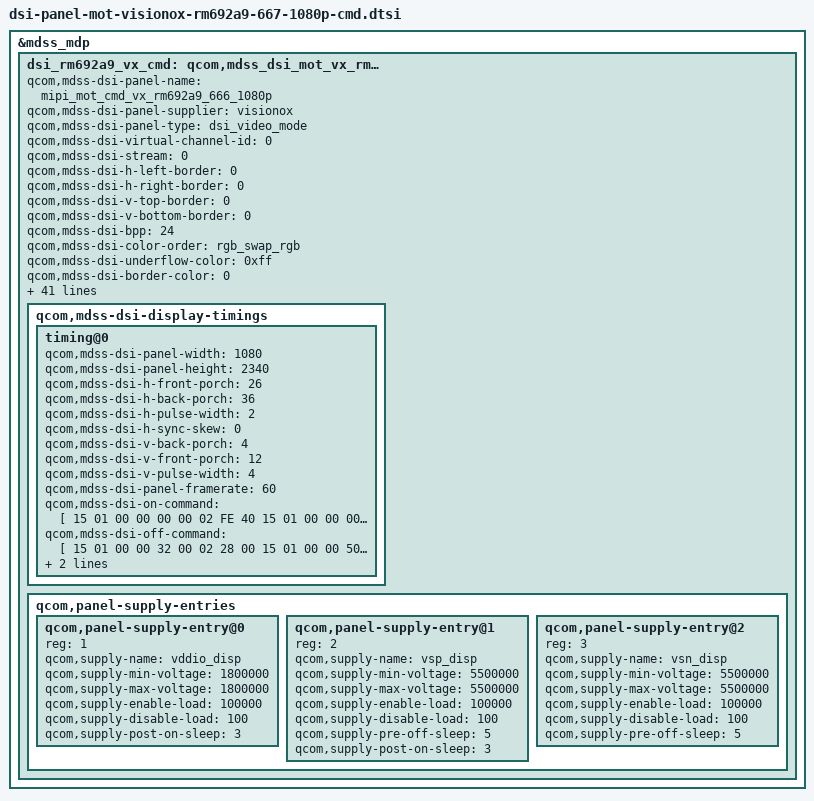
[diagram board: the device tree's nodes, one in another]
/* Copyright (c) 2016-2019, The Linux Foundation. All rights reserved.
 *
 * This program is free software; you can redistribute it and/or modify
 * it under the terms of the GNU General Public License version 2 and
 * only version 2 as published by the Free Software Foundation.
 *
 * This program is distributed in the hope that it will be useful,
 * but WITHOUT ANY WARRANTY; without even the implied warranty of
 * MERCHANTABILITY or FITNESS FOR A PARTICULAR PURPOSE.  See the
 * GNU General Public License for more details.
 */

&mdss_mdp {
	dsi_rm692a9_vx_cmd: qcom,mdss_dsi_mot_vx_rm692a9_667_1080x2340_cmd {
		qcom,mdss-dsi-panel-name = "mipi_mot_cmd_vx_rm692a9_666_1080p";
		qcom,mdss-dsi-panel-supplier = "visionox";
		qcom,mdss-dsi-panel-type = "dsi_video_mode";
		qcom,mdss-dsi-virtual-channel-id = <0>;
		qcom,mdss-dsi-stream = <0>;
		qcom,mdss-dsi-h-left-border = <0>;
		qcom,mdss-dsi-h-right-border = <0>;
		qcom,mdss-dsi-v-top-border = <0>;
		qcom,mdss-dsi-v-bottom-border = <0>;
		qcom,mdss-dsi-bpp = <24>;
		qcom,mdss-dsi-color-order = "rgb_swap_rgb";
		qcom,mdss-dsi-underflow-color = <0xff>;
		qcom,mdss-dsi-border-color = <0>;
		qcom,mdss-dsi-h-sync-pulse = <0>;
		qcom,dsi-ctrl-num = <0>;
		qcom,dsi-phy-num = <0>;
		qcom,mdss-dsi-traffic-mode = "non_burst_sync_event";
		qcom,mdss-dsi-lane-map = "lane_map_0123";
		qcom,mdss-dsi-bllp-eof-power-mode;
		qcom,mdss-dsi-bllp-power-mode;
		qcom,mdss-dsi-tx-eot-append;
		qcom,mdss-dsi-lane-0-state;
		qcom,mdss-dsi-lane-1-state;
		qcom,mdss-dsi-lane-2-state;
		qcom,mdss-dsi-lane-3-state;
		qcom,mdss-dsi-dma-trigger = "trigger_sw";
		qcom,mdss-dsi-mdp-trigger = "none";
		qcom,mdss-dsi-lp11-init;

		qcom,mdss-dsi-reset-assert-time = <5>;
		qcom,mdss-dsi-reset-sequence = <1 4>, <0 1>, <1 11>;
		qcom,mdss-pan-physical-width-dimension = <69>;
		qcom,mdss-pan-physical-height-dimension = <155>;

		qcom,mdss-dsi-no-panel-on-read-support;
		qcom,mdss-dsi-bl-min-level = <1>;
		qcom,mdss-dsi-bl-max-level = <2047>;
		qcom,mdss-brightness-max-level = <255>;
		qcom,bklt-dcs-2bytes-enabled;
		qcom,mdss-dsi-bl-pmic-control-type = "bl_ctrl_dcs";

		qcom,dsi-select-clocks = "mux_byte_clk0", "mux_pixel_clk0";
		qcom,mdss-dsi-cabc-mv-command = [15 01 00 00 00 00 02 55 03];
		qcom,mdss-dsi-cabc-mv-command-state =  "dsi_lp_mode";
		qcom,mdss-dsi-cabc-ui-command = [15 01 00 00 00 00 02 55 01];
		qcom,mdss-dsi-cabc-ui-command-state =  "dsi_lp_mode";
		qcom,mdss-dsi-cabc-dis-command = [15 01 00 00 00 00 02 55 00];
		qcom,mdss-dsi-cabc-dis-command-state =  "dsi_lp_mode";

		qcom,mdss-dsi-display-timings {
			timing@0 {
				qcom,mdss-dsi-panel-width = <1080>;
				qcom,mdss-dsi-panel-height = <2340>;
				qcom,mdss-dsi-h-front-porch = <26>;
				qcom,mdss-dsi-h-back-porch = <36>;
				qcom,mdss-dsi-h-pulse-width = <2>;
				qcom,mdss-dsi-h-sync-skew = <0>;
				qcom,mdss-dsi-v-back-porch = <4>;
				qcom,mdss-dsi-v-front-porch = <12>;
				qcom,mdss-dsi-v-pulse-width = <4>;
				qcom,mdss-dsi-panel-framerate = <60>;
				qcom,mdss-dsi-on-command =
				[
					15 01 00 00 00 00 02 FE 40
					15 01 00 00 00 00 02 9A 01
					15 01 00 00 00 00 02 FE 00
					15 01 00 00 00 00 02 C2 08
					15 01 00 00 00 00 02 35 00
					39 01 00 00 00 00 03 51 00 00
					15 01 00 00 78 00 02 11 00
					15 01 00 00 00 00 02 29 00
				];
				qcom,mdss-dsi-off-command = [
					15 01 00 00 32 00 02 28 00
					15 01 00 00 50 00 02 10 00
				];
				qcom,mdss-dsi-on-command-state = "dsi_lp_mode";
				qcom,mdss-dsi-off-command-state = "dsi_lp_mode";
			};
		};

		qcom,panel-supply-entries {
			#address-cells = <1>;
			#size-cells = <0>;

			qcom,panel-supply-entry@0 {
				reg = <1>;
				qcom,supply-name = "vddio_disp";
				qcom,supply-min-voltage = <1800000>;
				qcom,supply-max-voltage = <1800000>;
				qcom,supply-enable-load = <100000>;
				qcom,supply-disable-load = <100>;
				qcom,supply-post-on-sleep = <3>;
			};

			qcom,panel-supply-entry@1 {
				reg = <2>;
				qcom,supply-name = "vsp_disp";
				qcom,supply-min-voltage = <5500000>;
				qcom,supply-max-voltage = <5500000>;
				qcom,supply-enable-load = <100000>;
				qcom,supply-disable-load = <100>;
				qcom,supply-pre-off-sleep = <5>;
				qcom,supply-post-on-sleep = <3>;
			};

			qcom,panel-supply-entry@2 {
				reg = <3>;
				qcom,supply-name = "vsn_disp";
				qcom,supply-min-voltage = <5500000>;
				qcom,supply-max-voltage = <5500000>;
				qcom,supply-enable-load = <100000>;
				qcom,supply-disable-load = <100>;
				qcom,supply-pre-off-sleep = <5>;
			};
		};

	};
};
